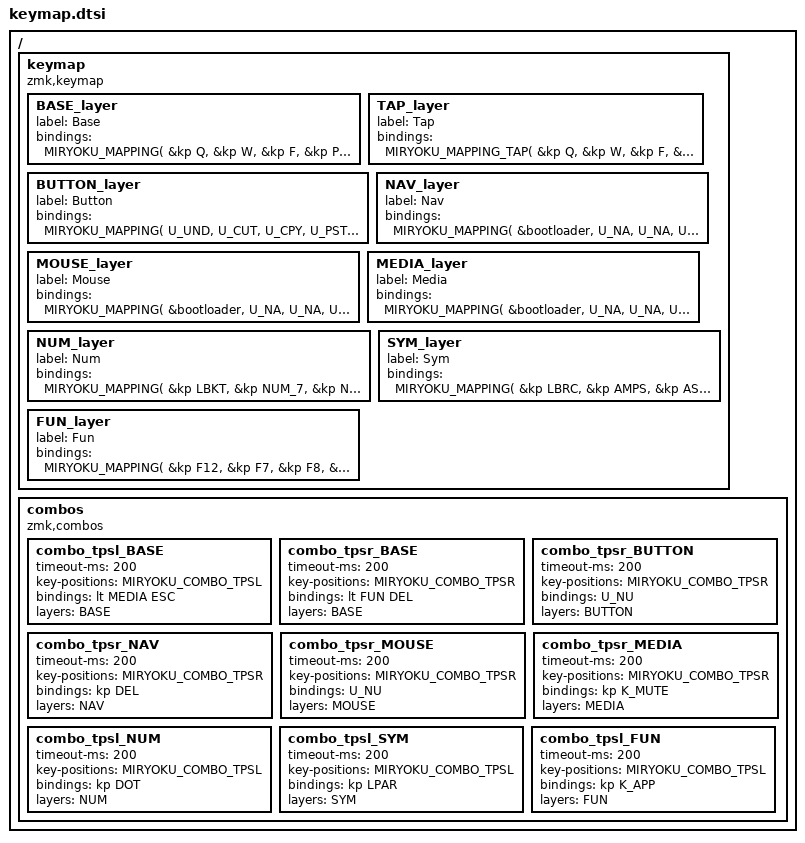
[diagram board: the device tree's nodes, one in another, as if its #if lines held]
// Copyright 2021 Manna Harbour
// https://github.com/manna-harbour/miryoku
// generated -*- buffer-read-only: t -*-


/ {
  keymap {
    compatible = "zmk,keymap";
    BASE_layer {
      label = "Base";
      bindings = <
#if defined MIRYOKU_ALPHAS_COLEMAK
        MIRYOKU_MAPPING(
&kp Q,           &kp W,           &kp F,           &kp P,           &kp B,           &kp J,           &kp L,           &kp U,           &kp Y,           &kp SQT,
&hm LGUI A,      &hm LALT R,      &hm LCTRL S,     &hm LSHFT T,     &kp G,           &kp M,           &hm LSHFT N,     &hm LCTRL E,     &hm LALT I,      &hm LGUI O,
&lt BUTTON Z,    &hm RALT X,      &kp C,           &kp D,           &kp V,           &kp K,           &kp H,           &kp COMMA,       &hm RALT DOT,    &lt BUTTON SLASH,
U_NP,            U_NP,            &lt MEDIA ESC,   &lt NAV SPC,     &lt MOUSE TAB,   &lt SYM RET,     &lt NUM BSPC,    &lt FUN DEL,     U_NP,            U_NP
        )
#elif defined MIRYOKU_ALPHAS_COLEMAKDHK
        MIRYOKU_MAPPING(
&kp Q,           &kp W,           &kp F,           &kp P,           &kp B,           &kp J,           &kp L,           &kp U,           &kp Y,           &kp SQT,
&hm LGUI A,      &hm LALT R,      &hm LCTRL S,     &hm LSHFT T,     &kp G,           &kp M,           &hm LSHFT N,     &hm LCTRL E,     &hm LALT I,      &hm LGUI O,
&lt BUTTON Z,    &hm RALT X,      &kp C,           &kp D,           &kp V,           &kp K,           &kp H,           &kp COMMA,       &hm RALT DOT,    &lt BUTTON SLASH,
U_NP,            U_NP,            &lt MEDIA ESC,   &lt NAV SPC,     &lt MOUSE TAB,   &lt SYM RET,     &lt NUM BSPC,    &lt FUN DEL,     U_NP,            U_NP
        )
#elif defined MIRYOKU_ALPHAS_DVORAK
        MIRYOKU_MAPPING(
&kp Q,           &kp W,           &kp F,           &kp P,           &kp B,           &kp J,           &kp L,           &kp U,           &kp Y,           &kp SQT,
&hm LGUI A,      &hm LALT R,      &hm LCTRL S,     &hm LSHFT T,     &kp G,           &kp M,           &hm LSHFT N,     &hm LCTRL E,     &hm LALT I,      &hm LGUI O,
&lt BUTTON Z,    &hm RALT X,      &kp C,           &kp D,           &kp V,           &kp K,           &kp H,           &kp COMMA,       &hm RALT DOT,    &lt BUTTON SLASH,
U_NP,            U_NP,            &lt MEDIA ESC,   &lt NAV SPC,     &lt MOUSE TAB,   &lt SYM RET,     &lt NUM BSPC,    &lt FUN DEL,     U_NP,            U_NP
        )
#elif defined MIRYOKU_ALPHAS_HALMAK
        MIRYOKU_MAPPING(
&kp Q,           &kp W,           &kp F,           &kp P,           &kp B,           &kp J,           &kp L,           &kp U,           &kp Y,           &kp SQT,
&hm LGUI A,      &hm LALT R,      &hm LCTRL S,     &hm LSHFT T,     &kp G,           &kp M,           &hm LSHFT N,     &hm LCTRL E,     &hm LALT I,      &hm LGUI O,
&lt BUTTON Z,    &hm RALT X,      &kp C,           &kp D,           &kp V,           &kp K,           &kp H,           &kp COMMA,       &hm RALT DOT,    &lt BUTTON SLASH,
U_NP,            U_NP,            &lt MEDIA ESC,   &lt NAV SPC,     &lt MOUSE TAB,   &lt SYM RET,     &lt NUM BSPC,    &lt FUN DEL,     U_NP,            U_NP
        )
#elif defined MIRYOKU_ALPHAS_WORKMAN
        MIRYOKU_MAPPING(
&kp Q,           &kp W,           &kp F,           &kp P,           &kp B,           &kp J,           &kp L,           &kp U,           &kp Y,           &kp SQT,
&hm LGUI A,      &hm LALT R,      &hm LCTRL S,     &hm LSHFT T,     &kp G,           &kp M,           &hm LSHFT N,     &hm LCTRL E,     &hm LALT I,      &hm LGUI O,
&lt BUTTON Z,    &hm RALT X,      &kp C,           &kp D,           &kp V,           &kp K,           &kp H,           &kp COMMA,       &hm RALT DOT,    &lt BUTTON SLASH,
U_NP,            U_NP,            &lt MEDIA ESC,   &lt NAV SPC,     &lt MOUSE TAB,   &lt SYM RET,     &lt NUM BSPC,    &lt FUN DEL,     U_NP,            U_NP
        )
#elif defined MIRYOKU_ALPHAS_QWERTY
        MIRYOKU_MAPPING(
&kp Q,           &kp W,           &kp F,           &kp P,           &kp B,           &kp J,           &kp L,           &kp U,           &kp Y,           &kp SQT,
&hm LGUI A,      &hm LALT R,      &hm LCTRL S,     &hm LSHFT T,     &kp G,           &kp M,           &hm LSHFT N,     &hm LCTRL E,     &hm LALT I,      &hm LGUI O,
&lt BUTTON Z,    &hm RALT X,      &kp C,           &kp D,           &kp V,           &kp K,           &kp H,           &kp COMMA,       &hm RALT DOT,    &lt BUTTON SLASH,
U_NP,            U_NP,            &lt MEDIA ESC,   &lt NAV SPC,     &lt MOUSE TAB,   &lt SYM RET,     &lt NUM BSPC,    &lt FUN DEL,     U_NP,            U_NP
        )
#else
        MIRYOKU_MAPPING(
&kp Q,           &kp W,           &kp F,           &kp P,           &kp B,           &kp J,           &kp L,           &kp U,           &kp Y,           &kp SQT,
&hm LGUI A,      &hm LALT R,      &hm LCTRL S,     &hm LSHFT T,     &kp G,           &kp M,           &hm LSHFT N,     &hm LCTRL E,     &hm LALT I,      &hm LGUI O,
&lt BUTTON Z,    &hm RALT X,      &kp C,           &kp D,           &kp V,           &kp K,           &kp H,           &kp COMMA,       &hm RALT DOT,    &lt BUTTON SLASH,
U_NP,            U_NP,            &lt MEDIA ESC,   &lt NAV SPC,     &lt MOUSE TAB,   &lt SYM RET,     &lt NUM BSPC,    &lt FUN DEL,     U_NP,            U_NP
        )
#endif
      >;
    };
    TAP_layer {
      label = "Tap";
      bindings = <
#if defined MIRYOKU_ALPHAS_COLEMAK
        MIRYOKU_MAPPING_TAP(
  &kp Q,           &kp W,           &kp F,           &kp P,           &kp G,           &kp J,           &kp L,           &kp U,           &kp Y,           &kp SQT,
  &kp A,           &kp R,           &kp S,           &kp T,           &kp D,           &kp H,           &kp N,           &kp E,           &kp I,           &kp O,
  &kp Z,           &kp X,           &kp C,           &kp V,           &kp B,           &kp K,           &kp M,           &kp COMMA,       &kp DOT,         &kp SLASH
          )
#elif defined MIRYOKU_ALPHAS_COLEMAKDHK
        MIRYOKU_MAPPING_TAP(
  &kp Q,           &kp W,           &kp F,           &kp P,           &kp B,           &kp J,           &kp L,           &kp U,           &kp Y,           &kp SQT,
  &kp A,           &kp R,           &kp S,           &kp T,           &kp G,           &kp K,           &kp N,           &kp E,           &kp I,           &kp O,
  &kp Z,           &kp X,           &kp C,           &kp D,           &kp V,           &kp M,           &kp H,           &kp COMMA,       &kp DOT,         &kp SLASH
          )
#elif defined MIRYOKU_ALPHAS_DVORAK
        MIRYOKU_MAPPING_TAP(
  &kp SQT,         &kp COMMA,       &kp DOT,         &kp P,           &kp Y,           &kp F,           &kp G,           &kp C,           &kp R,           &kp L,
  &kp A,           &kp O,           &kp E,           &kp U,           &kp I,           &kp D,           &kp H,           &kp T,           &kp N,           &kp S,
  &kp SLASH,       &kp Q,           &kp J,           &kp K,           &kp X,           &kp B,           &kp M,           &kp W,           &kp V,           &kp Z
          )
#elif defined MIRYOKU_ALPHAS_HALMAK
        MIRYOKU_MAPPING_TAP(
  &kp W,           &kp L,           &kp R,           &kp B,           &kp Z,           &kp SQT,         &kp Q,           &kp U,           &kp D,           &kp J,
  &kp S,           &kp H,           &kp N,           &kp T,           &kp COMMA,       &kp DOT,         &kp A,           &kp E,           &kp O,           &kp I,
  &kp F,           &kp M,           &kp V,           &kp C,           &kp SLASH,       &kp G,           &kp P,           &kp X,           &kp K,           &kp Y
          )
#elif defined MIRYOKU_ALPHAS_WORKMAN
        MIRYOKU_MAPPING_TAP(
  &kp Q,           &kp D,           &kp R,           &kp W,           &kp B,           &kp J,           &kp F,           &kp U,           &kp P,           &kp SQT,
  &kp A,           &kp S,           &kp H,           &kp T,           &kp G,           &kp Y,           &kp N,           &kp E,           &kp O,           &kp I,
  &kp Z,           &kp X,           &kp M,           &kp C,           &kp V,           &kp K,           &kp L,           &kp COMMA,       &kp DOT,         &kp SLASH
          )
#elif defined MIRYOKU_ALPHAS_QWERTY
        MIRYOKU_MAPPING_TAP(
  &kp Q,           &kp W,           &kp E,           &kp R,           &kp T,           &kp Y,           &kp U,           &kp I,           &kp O,           &kp P,
  &kp A,           &kp S,           &kp D,           &kp F,           &kp G,           &kp H,           &kp J,           &kp K,           &kp L,           &kp SQT,
  &kp Z,           &kp X,           &kp C,           &kp V,           &kp B,           &kp N,           &kp M,           &kp COMMA,       &kp DOT,         &kp SLASH
          )
#else
        MIRYOKU_MAPPING_TAP(
  &kp Q,           &kp W,           &kp F,           &kp P,           &kp B,           &kp J,           &kp L,           &kp U,           &kp Y,           &kp SQT,
  &kp A,           &kp R,           &kp S,           &kp T,           &kp G,           &kp M,           &kp N,           &kp E,           &kp I,           &kp O,
  &kp Z,           &kp X,           &kp C,           &kp D,           &kp V,           &kp K,           &kp H,           &kp COMMA,       &kp DOT,         &kp SLASH
          )
#endif
      >;
    };
    BUTTON_layer {
      label = "Button";
      bindings = <
        MIRYOKU_MAPPING(
U_UND,           U_CUT,           U_CPY,           U_PST,           U_RDO,           U_RDO,           U_PST,           U_CPY,           U_CUT,           U_UND,
&kp LGUI,        &kp LALT,        &kp LCTRL,       &kp LSHFT,       &trans,          &trans,          &kp LSHFT,       &kp LCTRL,       &kp LALT,        &kp LGUI,
U_UND,           U_CUT,           U_CPY,           U_PST,           U_RDO,           U_RDO,           U_PST,           U_CPY,           U_CUT,           U_UND,
U_NP,            U_NP,            U_NU,            U_NU,            &kp KP_N5,       &kp KP_N5,       U_NU,            U_NU,            U_NP,            U_NP
        )
      >;
    };
    NAV_layer {
      label = "Nav";
      bindings = <
#if defined MIRYOKU_NAV_VI
        MIRYOKU_MAPPING(
&bootloader,     U_NA,            U_NA,            U_NA,            U_NA,            U_RDO,           U_PST,           U_CPY,           U_CUT,           U_UND,
&kp LGUI,        &kp LALT,        &kp LCTRL,       &kp LSHFT,       U_NA,            &kp LEFT,        &kp DOWN,        &kp UP,          &kp RIGHT,       &kp CAPS,
U_NA,            &kp RALT,        U_NA,            U_NA,            U_NA,            &kp HOME,        &kp PG_DN,       &kp PG_UP,       &kp END,         &kp INS,
U_NP,            U_NP,            U_NA,            U_NA,            U_NA,            &kp RET,         &kp BSPC,        &kp DEL,         U_NP,            U_NP
        )
#else
        MIRYOKU_MAPPING(
&bootloader,     U_NA,            U_NA,            U_NA,            U_NA,            U_RDO,           U_PST,           U_CPY,           U_CUT,           U_UND,
&kp LGUI,        &kp LALT,        &kp LCTRL,       &kp LSHFT,       U_NA,            &kp CAPS,        &kp LEFT,        &kp DOWN,        &kp UP,          &kp RIGHT,
U_NA,            &kp RALT,        U_NA,            U_NA,            U_NA,            &kp INS,         &kp HOME,        &kp PG_DN,       &kp PG_UP,       &kp END,
U_NP,            U_NP,            U_NA,            U_NA,            U_NA,            &kp RET,         &kp BSPC,        &kp DEL,         U_NP,            U_NP
        )
#endif
      >;
    };
    MOUSE_layer {
      label = "Mouse";
      bindings = <
#if defined MIRYOKU_NAV_VI
        MIRYOKU_MAPPING(
&bootloader,     U_NA,            U_NA,            U_NA,            U_NA,            U_RDO,           U_PST,           U_CPY,           U_CUT,           U_UND,
&kp LGUI,        &kp LALT,        &kp LCTRL,       &kp LSHFT,       U_NA,            &kp KP_N4,       &kp KP_N2,       &kp KP_N8,       &kp KP_N6,       U_NU,
U_NA,            &kp RALT,        U_NA,            U_NA,            U_NA,            U_NU,            U_NU,            U_NU,            U_NU,            U_NU,
U_NP,            U_NP,            U_NA,            U_NA,            U_NA,            &kp KP_N5,       U_NU,            U_NU,            U_NP,            U_NP
        )
#else
        MIRYOKU_MAPPING(
&bootloader,     U_NA,            U_NA,            U_NA,            U_NA,            U_RDO,           U_PST,           U_CPY,           U_CUT,           U_UND,
&kp LGUI,        &kp LALT,        &kp LCTRL,       &kp LSHFT,       U_NA,            U_NU,            &kp KP_N4,       &kp KP_N2,       &kp KP_N8,       &kp KP_N6,
U_NA,            &kp RALT,        U_NA,            U_NA,            U_NA,            U_NU,            U_NU,            U_NU,            U_NU,            U_NU,
U_NP,            U_NP,            U_NA,            U_NA,            U_NA,            &kp KP_N5,       U_NU,            U_NU,            U_NP,            U_NP
        )
#endif
      >;
    };
    MEDIA_layer {
      label = "Media";
      bindings = <
#if defined MIRYOKU_NAV_VI
        MIRYOKU_MAPPING(
&bootloader,     U_NA,            U_NA,            U_NA,            U_NA,            &rgb_ug RGB_TOG, &rgb_ug RGB_EFF, &rgb_ug RGB_HUI, &rgb_ug RGB_SAI, &rgb_ug RGB_BRI,
&kp LGUI,        &kp LALT,        &kp LCTRL,       &kp LSHFT,       U_NA,            &kp C_PREV,      &kp C_VOL_DN,    &kp C_VOL_UP,    &kp C_NEXT,      &out OUT_TOG,
U_NA,            &kp RALT,        U_NA,            U_NA,            U_NA,            &bt BT_SEL 0,    &bt BT_SEL 1,    &bt BT_SEL 2,    &bt BT_SEL 3,    &bt BT_CLR,
U_NP,            U_NP,            U_NA,            U_NA,            U_NA,            &kp C_STOP,      &kp C_PP,        &kp C_MUTE,      U_NP,            U_NP
        )
#else
        MIRYOKU_MAPPING(
&bootloader,     U_NA,            U_NA,            U_NA,            U_NA,            &rgb_ug RGB_TOG, &rgb_ug RGB_EFF, &rgb_ug RGB_HUI, &rgb_ug RGB_SAI, &rgb_ug RGB_BRI,
&kp LGUI,        &kp LALT,        &kp LCTRL,       &kp LSHFT,       U_NA,            &out OUT_TOG,    &kp C_PREV,      &kp C_VOL_DN,    &kp C_VOL_UP,    &kp C_NEXT,
U_NA,            &kp RALT,        U_NA,            U_NA,            U_NA,            &bt BT_CLR,      &bt BT_SEL 0,    &bt BT_SEL 1,    &bt BT_SEL 2,    &bt BT_SEL 3,
U_NP,            U_NP,            U_NA,            U_NA,            U_NA,            &kp C_STOP,      &kp C_PP,        &kp C_MUTE,      U_NP,            U_NP
        )
#endif
      >;
    };
    NUM_layer {
      label = "Num";
      bindings = <
        MIRYOKU_MAPPING(
&kp LBKT,        &kp NUM_7,       &kp NUM_8,       &kp NUM_9,       &kp RBKT,        U_NA,            U_NA,            U_NA,            U_NA,            &bootloader,
&kp SEMI,        &kp NUM_4,       &kp NUM_5,       &kp NUM_6,       &kp EQL,         U_NA,            &kp LSHFT,       &kp LCTRL,       &kp LALT,        &kp LGUI,
&kp GRAVE,       &kp NUM_1,       &kp NUM_2,       &kp NUM_3,       &kp BSLH,        U_NA,            U_NA,            U_NA,            &kp RALT,        U_NA,
U_NP,            U_NP,            &kp DOT,         &kp NUM_0,       &kp MINUS,       U_NA,            U_NA,            U_NA,            U_NP,            U_NP
        )
      >;
    };
    SYM_layer {
      label = "Sym";
      bindings = <
        MIRYOKU_MAPPING(
&kp LBRC,        &kp AMPS,        &kp ASTRK,       &kp LPAR,        &kp RBRC,        U_NA,            U_NA,            U_NA,            U_NA,            &bootloader,
&kp COLON,       &kp DLLR,        &kp PRCT,        &kp CRRT,        &kp PLUS,        U_NA,            &kp LSHFT,       &kp LCTRL,       &kp LALT,        &kp LGUI,
&kp TILDE,       &kp EXCL,        &kp AT,          &kp HASH,        &kp PIPE,        U_NA,            U_NA,            U_NA,            &kp RALT,        U_NA,
U_NP,            U_NP,            &kp LPAR,        &kp RPAR,        &kp UNDER,       U_NA,            U_NA,            U_NA,            U_NP,            U_NP
        )
      >;
    };
    FUN_layer {
      label = "Fun";
      bindings = <
        MIRYOKU_MAPPING(
&kp F12,         &kp F7,          &kp F8,          &kp F9,          &kp PSCRN,       U_NA,            U_NA,            U_NA,            U_NA,            &bootloader,
&kp F11,         &kp F4,          &kp F5,          &kp F6,          &kp SLCK,        U_NA,            &kp LSHFT,       &kp LCTRL,       &kp LALT,        &kp LGUI,
&kp F10,         &kp F1,          &kp F2,          &kp F3,          &kp PAUSE_BREAK, U_NA,            U_NA,            U_NA,            &kp RALT,        U_NA,
U_NP,            U_NP,            &kp K_APP,       &kp SPC,         &kp TAB,         U_NA,            U_NA,            U_NA,            U_NP,            U_NP
        )
      >;
    };
  };
};

#if defined (MIRYOKU_COMBO_TPS_ENABLE) && defined (MIRYOKU_COMBO_TPSL) && defined (MIRYOKU_COMBO_TPSR)
/ {
  combos {
    compatible = "zmk,combos";
    combo_tpsl_BASE {
      timeout-ms = <200>;
      key-positions = <MIRYOKU_COMBO_TPSL>;
      bindings = <&lt MEDIA ESC>;
      layers = <BASE>;
    };
    combo_tpsr_BASE {
      timeout-ms = <200>;
      key-positions = <MIRYOKU_COMBO_TPSR>;
      bindings = <&lt FUN DEL>;
      layers = <BASE>;
    };
    combo_tpsr_BUTTON {
      timeout-ms = <200>;
      key-positions = <MIRYOKU_COMBO_TPSR>;
      bindings = <U_NU>;
      layers = <BUTTON>;
    };
    combo_tpsr_NAV {
      timeout-ms = <200>;
      key-positions = <MIRYOKU_COMBO_TPSR>;
      bindings = <&kp DEL>;
      layers = <NAV>;
    };
    combo_tpsr_MOUSE {
      timeout-ms = <200>;
      key-positions = <MIRYOKU_COMBO_TPSR>;
      bindings = <U_NU>;
      layers = <MOUSE>;
    };
    combo_tpsr_MEDIA {
      timeout-ms = <200>;
      key-positions = <MIRYOKU_COMBO_TPSR>;
      bindings = <&kp K_MUTE>;
      layers = <MEDIA>;
    };
    combo_tpsl_NUM {
      timeout-ms = <200>;
      key-positions = <MIRYOKU_COMBO_TPSL>;
      bindings = <&kp DOT>;
      layers = <NUM>;
    };
    combo_tpsl_SYM {
      timeout-ms = <200>;
      key-positions = <MIRYOKU_COMBO_TPSL>;
      bindings = <&kp LPAR>;
      layers = <SYM>;
    };
    combo_tpsl_FUN {
      timeout-ms = <200>;
      key-positions = <MIRYOKU_COMBO_TPSL>;
      bindings = <&kp K_APP>;
      layers = <FUN>;
    };
  };
};
#endif
